# PIC32MZ1025DAK176 device description
Architecture: MIPS; Family: PIC32MZDA; Series: PIC32MZ
Registers are 32-bit, read-write, no defined reset value unless marked. A register's access mark holds for its fields unless they carry their own. Offsets are from the block's base; [hi:lo] are bit positions; 'fields as' and 'values as' point back to an identical list.

## SDHC
Instances: SDHC 0x1f8ec004 in periph_indep
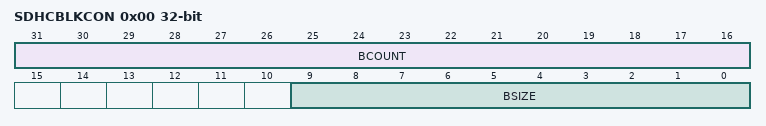
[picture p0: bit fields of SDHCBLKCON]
0x00 SDHCBLKCON — SDHC Block Control Register
  [31:16] BCOUNT — Blocks Count for Current Transfer bits
    0=65,535 blocks; 0=2 blocks; 0=1 block; 0=Stop count Blocks Count for Current Transfer bits
  [9:0] BSIZE — Transfer Block Size bits
    0x200=512 bytes; 0x1ff=511 bytes; 2=2 bytes; 1=1 byte; 0=No data transfer

## TMR1
Instances: TMR1 0x1f840000 in periph_pb3_std
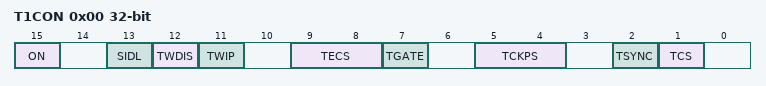
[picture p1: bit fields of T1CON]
0x00 T1CON — TYPE A TIMER CONTROL REGISTER
  [15] ON — Timer On bit
    1=Timer is enabled; 0=Timer is disabled
  [13] SIDL — Stop in Idle Mode bit
    1=Discontinue operation when device enters Idle mode; 0=Continue operation even in Idle mode
  [12] TWDIS — Asynchronous Timer Write Disable bit
    1=Writes to TMR1 are ignored until pending write operation completes; 0=Back-to-back writes are enabled (Legacy Asynchronous Timer functionality)
  [11] TWIP — Asynchronous Timer Write in Progress bit
    1=(In Asynchronous Timer mode) Asynchronous write to TMR1 register in progress / (In Synchronous Timer mode)bit is read as 0; 0=In Asynchronous Timer mode Asynchronous write to TMR1 register complete / (In Synchronous Timer mode)bit is read as 0
  [9:8] TECS — Timer1 External Clock Selection bits
    2=External clock comes from the LPRC; 1=External clock comes from the T1CK pin; 0=External clock comes from the SOSC
  [7] TGATE — Timer Gated Time Accumulation Enable bit
    1=(When TCS is 0) Gated time accumulation is enabled / (When TCS is 1) bit is ignored; 0=(When TCS is 0) Gated time accumulation is disabled / (When TCS is 1) bit is ignored
  [5:4] TCKPS — Timer Input Clock Prescale Select bits
    3=1:256 prescale value; 2=1:64 prescale value; 1=1:8 prescale value; 0=1:1 prescale value
  [2] TSYNC — Timer External Clock Input Synchronization Selection bit
    1=(When TCS is 1) External clock input is synchronized / (When TCS is 0) This bit is ignored; 0=(When TCS is 1) External clock input is not synchronized / (When TCS is 0) This bit is ignored
  [1] TCS — Timer Clock Source Select bit
    1=External clock is defined by the TECS bits; 0=Internal peripheral clock
0x10 TMR1 — Timer Count Register Bits
0x20 PR1 — Period Register Bits

## TMR
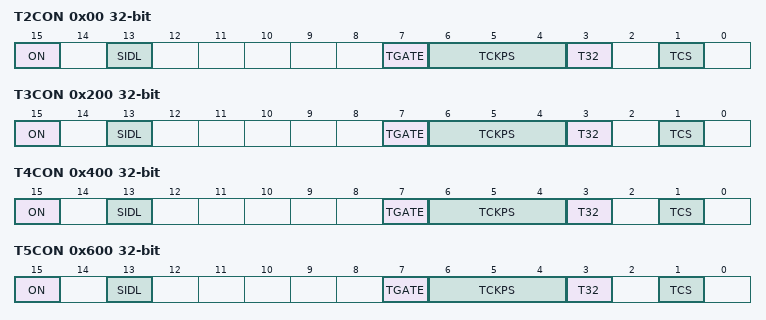
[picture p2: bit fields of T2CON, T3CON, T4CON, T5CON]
0x00 T2CON — Type B Timer Control Register
  [15] ON — Timer On bit
    1=Module is enabled; 0=Module is disabled
  [13] SIDL — Stop in Idle Mode bit
    1=Discontinue operation when device enters Idle mode; 0=Continue operation even in Idle mode
  [7] TGATE — Timer Gated Time Accumulation Enable bit
    1=(When TCS is 1): Gated time accumulation is enabled / (When TCS=0): bit is ignored and read as 0; 0=(When TCS is 0): Gated time accumulation is disabled / (When TCS=0): bit is ignored and read as 0
  [6:4] TCKPS — Timer Input Clock Prescale Select bits
    7=1:256 prescale value; 6=1:64 prescale value; 5=1:32 prescale value; 4=1:16 prescale value; 3=1:8 prescale value; 2=1:4 prescale value; 1=1:2 prescale value; 0=1:1 prescale value
  [3] T32 — 32-Bit Timer Mode Select bit
    1=Odd numbered and even numbered timers form a 32-bit timer; 0=Odd numbered and even numbered timers form separate 16-bit timers
  [1] TCS — Timer Clock Source Select bit
    1=External clock from TxCK pin; 0=Internal peripheral clock
0x10 TMR2 — Timer Count Register Bits
0x20 PR2 — Period Register Bits
0x200 T3CON — Type B Timer Control Register
  fields as T2CON
0x210 TMR3
0x220 PR3
0x400 T4CON — Type B Timer Control Register
  fields as T2CON
0x410 TMR4
0x420 PR4
0x600 T5CON — Type B Timer Control Register
  fields as T2CON
0x610 TMR5
0x620 PR5
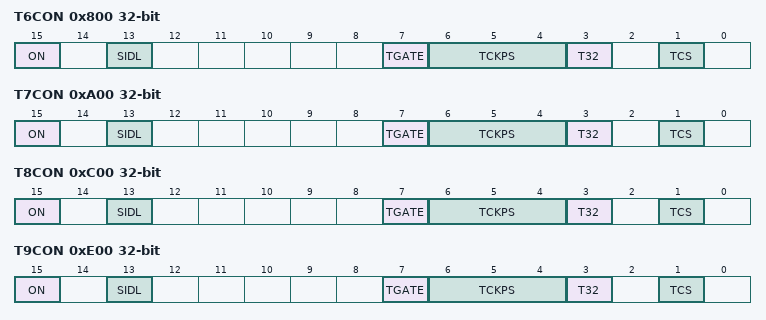
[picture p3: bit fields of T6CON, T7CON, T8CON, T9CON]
0x800 T6CON — Type B Timer Control Register
  fields as T2CON
0x810 TMR6
0x820 PR6
0xA00 T7CON — Type B Timer Control Register
  fields as T2CON
0xA10 TMR7
0xA20 PR7
0xC00 T8CON — Type B Timer Control Register
  fields as T2CON
0xC10 TMR8
0xC20 PR8
0xE00 T9CON — Type B Timer Control Register
  fields as T2CON
0xE10 TMR9
0xE20 PR9

## USBCLKRST
Instances: USBCLKRST 0x1f8e4000 in periph_pb5_std
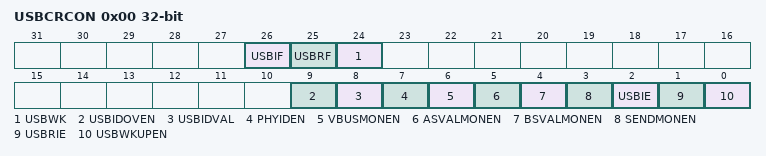
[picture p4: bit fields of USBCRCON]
0x00 USBCRCON — USB Clock/Reset Control Register
  [26] USBIF — USB General Interrupt Flag bit
    1=An event on the USB Bus has occurred; 0=No interrupt from USB module or interrupts have not been enabled
  [25] USBRF — USB Resume Flag bit
    1=Resume from Suspend state. Device wake-up activity can be started.; 0=No Resume activity detected during Suspend
  [24] USBWK — USB Activity Status bit
    1=Connect; 0=No activity detected on USB
  [9] USBIDOVEN — USB ID Override Enable bit
    1=Enable use of USBIDVAL bit; 0=Disable use of USBIDVAL and instead use the PHY value
  [8] USBIDVAL — USB ID Value bit
    1=ID override value is 1; 0=ID override value is 0
  [7] PHYIDEN — PHY ID Monitoring Enable bit
    1=Enable monitoring of the ID bit from the USB PHY; 0=Disable monitoring of the ID bit from the USB PHY
  [6] VBUSMONEN — Vbus Monitoring for OTG Enable bit
    1=Enable monitoring for Vbus in VBUS Valid range (between 4.4V and 4.75V); 0=Disable monitoring for Vbus in VBUS Valid range
  [5] ASVALMONEN — A-Device Vbus Monitoring for OTG Enable bit
    1=Enable monitoring for Vbus in Session Valid range for A-device (between 0.8V and 2.0V); 0=Disable monitoring for Vbus in Session Valid range for A-device
  [4] BSVALMONEN — B-Device Vbus Monitoring for OTG Enable bit
    1=Enable monitoring for Vbus in Session Valid range for B-device (between 0.8V and 4.0V); 0=Disable monitoring for Vbus in Session Valid range for B-device
  [3] SENDMONEN — Session End Vbus Monitoring for OTG Enable bit
    1=Enable monitoring for Vbus in Session End range (between 0.2V and 0.8V); 0=Disable monitoring for Vbus in Session End range
  [2] USBIE — USB General Interrupt Enable bit
    1=Enables general interrupt from USB module; 0=Disables general interrupt from USB module
  [1] USBRIE — USB Resume Interrupt Enable bit
    1=Enable remote resume from suspend Interrupt; 0=Disable interrupt to a Remote Devices USB resume signaling
  [0] USBWKUPEN — USB Activity Detection Interrupt Enable bit
    1=Enable interrupt for detection of activity on USB bus in Sleep mode; 0=Disable interrupt for detection of activity on USB bus in Sleep mode

## WDT
Instances: WDT 0x1f800800 in periph_pb1_std
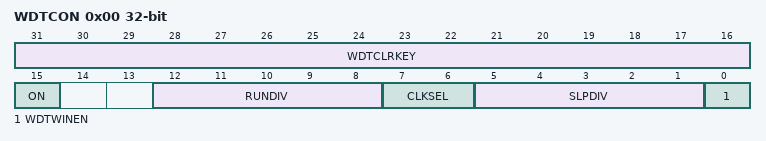
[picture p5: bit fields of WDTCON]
0x00 WDTCON — Watchdog Timer Control Register
  [31:16] WDTCLRKEY
  [15] ON — Watchdog Timer Enable bit
    1=The WDT is enabled; 0=The WDT is disabled
  [12:8] RUNDIV
  [7:6] CLKSEL
  [5:1] SLPDIV
  [0] WDTWINEN — Watchdog Timer Window Enable bit
    1=Enable windowed Watchdog Timer; 0=Disable windowed Watchdog Timer

## Notices in the file
Copyright (c) 2017 Microchip Technology Inc.
SPDX-License-Identifier: Apache-2.0
Licensed under the Apache License, Version 2.0 (the "License");
you may not use this file except in compliance with the License.
You may obtain a copy of the License at
http://www.apache.org/licenses/LICENSE-2.0
Unless required by applicable law or agreed to in writing, software
distributed under the License is distributed on an "AS IS" BASIS,
WITHOUT WARRANTIES OR CONDITIONS OF ANY KIND, either express or implied.
See the License for the specific language governing permissions and
limitations under the License.
